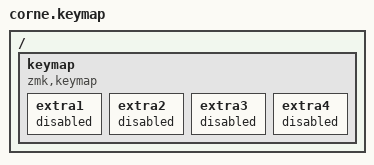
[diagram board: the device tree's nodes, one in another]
// Copyright 2021 Manna Harbour
// https://github.com/manna-harbour/miryoku

#include "../miryoku/custom_config.h"
#include "../miryoku/mapping/42/corne.h"
#include "../miryoku/miryoku.dtsi"

/ {
    keymap {
        compatible = "zmk,keymap";
        
        // ZMK Studio Reserved Layers
        extra1 { status = "reserved"; };
        extra2 { status = "reserved"; };
        extra3 { status = "reserved"; };
        extra4 { status = "reserved"; };
    };
};
